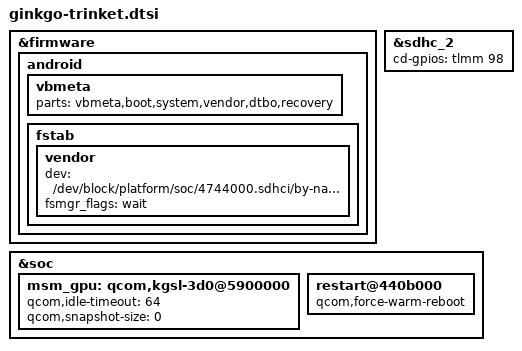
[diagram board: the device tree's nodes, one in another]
#include "../qcom-base/trinket-idp.dtsi"
#include "../qcom-base/pmi632.dtsi"
#include "ginkgo-trinket-audio.dtsi"
#include "ginkgo-trinket-battery.dtsi"
#include "ginkgo-trinket-camera.dtsi"
#include "ginkgo-trinket-display.dtsi"
#include "ginkgo-trinket-fingerprint.dtsi"
#include "ginkgo-trinket-ir.dtsi"
#include "ginkgo-trinket-led.dtsi"
#include "ginkgo-trinket-memory.dtsi"
#include "ginkgo-trinket-nfc.dtsi"
#include "ginkgo-trinket-pinctrl.dtsi"
#include "ginkgo-trinket-pm6125.dtsi"
#include "ginkgo-trinket-regulator.dtsi"
#include "ginkgo-trinket-thermal.dtsi"
#include "ginkgo-trinket-touchscreen.dtsi"
#include "ginkgo-trinket-usb.dtsi"
#include "ginkgo-trinket-vibrator.dtsi"

&firmware {
	android {
		vbmeta {
			parts = "vbmeta,boot,system,vendor,dtbo,recovery";
		};

		fstab {
			vendor {
				dev = "/dev/block/platform/soc/4744000.sdhci/by-name/vendor";
				fsmgr_flags = "wait";
			};
		};
	};
};

&sdhc_2 {
	cd-gpios = <&tlmm 98 0>;
};

&soc {
	msm_gpu: qcom,kgsl-3d0@5900000 {
		qcom,idle-timeout = <64>;

		/* size in bytes */
		qcom,snapshot-size = <0>;
	};
	
	restart@440b000 {
        qcom,force-warm-reboot;
    };
};
